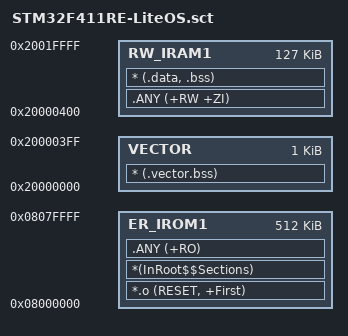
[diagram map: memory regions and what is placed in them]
; *************************************************************
; *** Scatter-Loading Description File generated by uVision ***
; *************************************************************

LR_IROM1 0x08000000 0x00080000  {    ; load region size_region
  ER_IROM1 0x08000000 0x00080000  {  ; load address = execution address
   *.o (RESET, +First)
   *(InRoot$$Sections)
   .ANY (+RO)
  }
  VECTOR 0x20000000 0x400 { ;vector
    * (.vector.bss)
  }

  RW_IRAM1 0x20000400 0x0001FC00  {  ; RW data
   .ANY (+RW +ZI)
   * (.data, .bss)
  }
}

